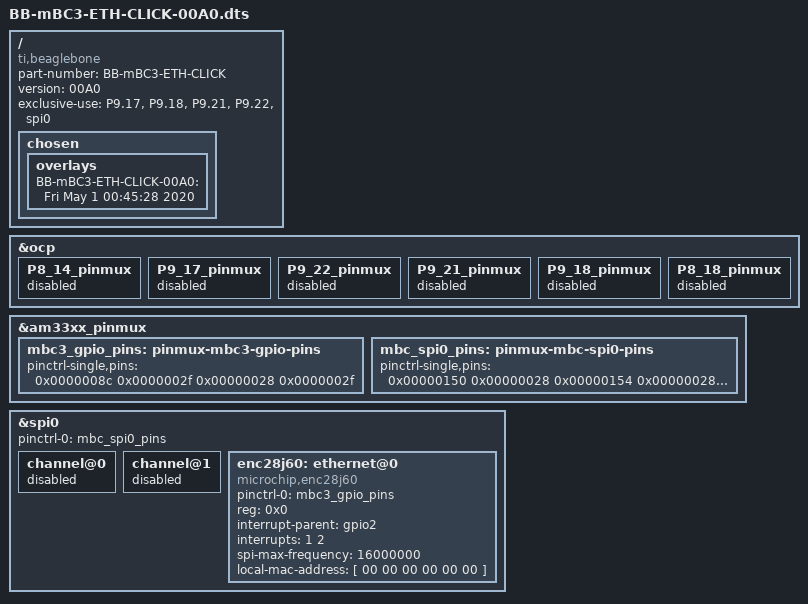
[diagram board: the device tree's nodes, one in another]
/*
 * Copyright (C) 2018 Robert Nelson <robertcnelson@gmail.com>
 *
 * This program is free software; you can redistribute it and/or modify
 * it under the terms of the GNU General Public License version 2 as
 * published by the Free Software Foundation.
 *
 * https://www.mikroe.com/eth-click
 * https://download.mikroe.com/documents/add-on-boards/click/eth/eth-click-manual-v100.pdf
 ^ https://github.com/beagleboard/bb.org-overlays/edit/master/src/arm/BB-mBC3-ETH-CLICK.dts
 *
 * Make sure to change the UART3 jumpers to SPI0 Mode...
 */

/dts-v1/;
/plugin/;

// #include <dt-bindings/gpio/gpio.h>
// #include <dt-bindings/pinctrl/am33xx.h>
// #include <dt-bindings/interrupt-controller/irq.h>

/ {
	compatible = "ti,beaglebone", "ti,beaglebone-black", "ti,beaglebone-green";

	/* identification */
	part-number = "BB-mBC3-ETH-CLICK";
	version = "00A0";

	/* state the resources this cape uses */
	exclusive-use =
		/* the pin header uses */
		"P9.17",	/* P9_17 (A16) spi0_cs0.spi0_cs0 */
		"P9.18",	/* P9_18 (B16) spi0_d1.spi0_d1 */
		"P9.21",	/* P9_21 (B17) spi0_d0.spi0_d0 */
		"P9.22",	/* P9_22 (A17) spi0_sclk.spi0_sclk */
		/* the hardware ip uses */
		"spi0";

	/*
	 * Helper to show loaded overlays under: /proc/device-tree/chosen/overlays/
	 */
	fragment@0 {
		target-path="/";
		__overlay__ {

			chosen {
				overlays {
					// BB-mBC3-ETH-CLICK-00A0 = __TIMESTAMP__;
					BB-mBC3-ETH-CLICK-00A0 = "Fri May  1 00:45:28 2020";
				};
			};
		};
	};

	/*
	 * Free up the pins used by the cape from the pinmux helpers.
	 */
	fragment@1 {
		target = <&ocp>;
		__overlay__ {
			P8_14_pinmux { status = "disabled"; };	/* RESET - gpio0[26] */

			/* Click 3 */
			P9_17_pinmux { status = "disabled"; };	/* CS - spi0_cs0 */

			P9_22_pinmux { status = "disabled"; };	/* SCK - spi0_sclk */
			P9_21_pinmux { status = "disabled"; };	/* MISO - spi0_d0 */
			P9_18_pinmux { status = "disabled"; };	/* MOSI - spi0_d1 */

			// P8_19_pinmux { status = "disabled"; };	/* PWM - ehrpwm2a */
			P8_18_pinmux { status = "disabled"; };	/* INT - gpio2[1] */

			//P9_26_pinmux { status = "disabled"; };	/* RX - uart1_rxd */
			//P9_24_pinmux { status = "disabled"; };	/* TX - uart1_txd */
			//P9_19_pinmux { status = "disabled"; };	/* SCL */
			//P9_20_pinmux { status = "disabled"; };	/* SDA */
		};
	};

	fragment@2 {
		target = <&am33xx_pinmux>;
		__overlay__ {
			mbc3_gpio_pins: pinmux-mbc3-gpio-pins {
				pinctrl-single,pins = <0x0000008c 0x0000002f 0x00000028 0x0000002f>;
				// pinctrl-single,pins = <
				//	AM33XX_IOPAD(0x088C, PIN_INPUT | MUX_MODE7 ) /* P8_18 (V12) gpmc_clk.gpio2[1] INT */
				//	AM33XX_IOPAD(0x0828, PIN_INPUT | MUX_MODE7 ) /* P8_14 (T11) gpmc_ad10.gpio0[26] RESET */
				// >;
			};

			mbc_spi0_pins: pinmux-mbc-spi0-pins {
				pinctrl-single,pins = <0x00000150 0x00000028 0x00000154 0x00000028 0x00000158 0x00000028 0x0000015c 0x00000028>;
				// pinctrl-single,pins = <
				//	AM33XX_IOPAD(0x0950, PIN_INPUT | MUX_MODE0 ) /* P9_22 (A17) spi0_sclk.spi0_sclk */
				//	AM33XX_IOPAD(0x0954, PIN_INPUT | MUX_MODE0 ) /* P9_21 (B17) spi0_d0.spi0_d0 */
				//	AM33XX_IOPAD(0x0958, PIN_INPUT | MUX_MODE0 ) /* P9_18 (B16) spi0_d1.spi0_d1 */

				//	/* Click 3 */
				//	AM33XX_IOPAD(0x095c, PIN_INPUT | MUX_MODE0 ) /* P9_17 (A16) spi0_cs0.spi0_cs0 */
				// >;
			};
		};
	};

	fragment@3 {
		target = <&spi0>;
		__overlay__ {
			status = "okay";
			pinctrl-names = "default";
			pinctrl-0 = <&mbc_spi0_pins>;

			channel@0{ status = "disabled"; };
			channel@1{ status = "disabled"; };
		};
	};

	fragment@4 {
		target = <&spi0>;
		__overlay__ {
			#address-cells = <1>;
			#size-cells = <0>;

			enc28j60: ethernet@0 {
				compatible = "microchip,enc28j60";
				pinctrl-names = "default";
				pinctrl-0 = <&mbc3_gpio_pins>;
				reg = <0x0>;
				interrupt-parent = <&gpio2>;
				interrupts = <1 2>; // <1 IRQ_TYPE_EDGE_FALLING>
				// interrupts = <1 IRQ_TYPE_EDGE_FALLING>;
				spi-max-frequency = <16000000>;
				local-mac-address = [ 00 00 00 00 00 00 ];
			};
		};
	};
};
